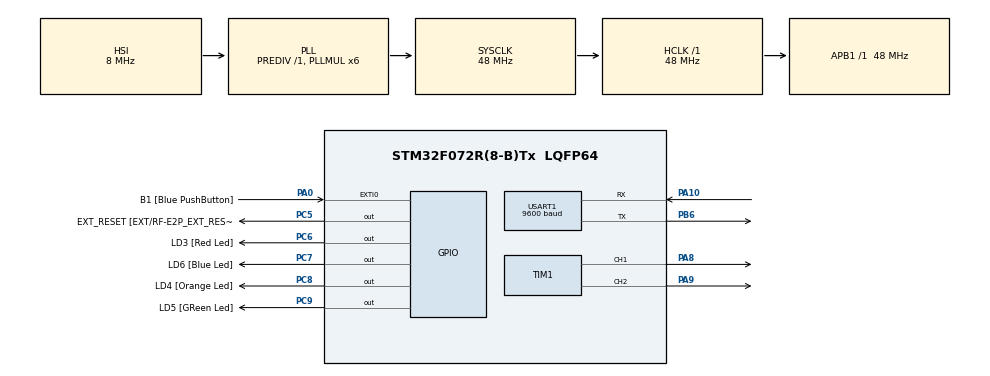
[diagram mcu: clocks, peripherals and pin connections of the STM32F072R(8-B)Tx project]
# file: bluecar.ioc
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Mcu.Family=STM32F0
Mcu.Name=STM32F072R(8-B)Tx
Mcu.Package=LQFP64
NVIC.TIM1_BRK_UP_TRG_COM_IRQn=true\:0\:0\:false\:false\:true
NVIC.TIM1_CC_IRQn=true\:0\:0\:false\:false\:true
NVIC.TIM2_IRQn=true\:0\:0\:false\:false\:true
NVIC.TimeBase=TIM2_IRQn
NVIC.TimeBaseIP=TIM2
NVIC.USART1_IRQn=true\:0\:0\:true\:true\:true\:1
PA0.GPIO_Label=B1 [Blue PushButton]
PA0.GPIO_ModeDefaultEXTI=GPIO_MODE_EVT_RISING
PA0.Signal=GPXTI0
PA10.Mode=Asynchronous
PA10.Signal=USART1_RX
PA13.GPIO_Label=SWDIO
PA13.Signal=SYS_SWDIO
PA14.GPIO_Label=SWCLK
PA14.Signal=SYS_SWCLK
PA8.Signal=S_TIM1_CH1
PA9.Signal=S_TIM1_CH2
PB6.Mode=Asynchronous
PB6.Signal=USART1_TX
PC5.GPIO_Label=EXT_RESET [EXT/RF-E2P_EXT_RESET]
PC5.Signal=GPIO_Output
PC6.GPIO_Label=LD3 [Red Led]
PC6.Signal=GPIO_Output
PC7.GPIO_Label=LD6 [Blue Led]
PC7.Signal=GPIO_Output
PC8.GPIO_Label=LD4 [Orange Led]
PC8.Signal=GPIO_Output
PC9.GPIO_Label=LD5 [GReen Led]
PC9.Signal=GPIO_Output
ProjectManager.HeapSize=0x200
ProjectManager.StackSize=0x400
ProjectManager.TargetToolchain=SW4STM32
RCC.AHBFreq_Value=48000000
RCC.APB1Freq_Value=48000000
RCC.APB1TimFreq_Value=48000000
RCC.HCLKFreq_Value=48000000
RCC.PLLMUL=RCC_PLL_MUL6
RCC.SYSCLKFreq_VALUE=48000000
RCC.SYSCLKSource=RCC_SYSCLKSOURCE_PLLCLK
SH.S_TIM1_CH1.0=TIM1_CH1,PWM Generation1 CH1
SH.S_TIM1_CH2.0=TIM1_CH2,PWM Generation2 CH2
TIM1.Channel-PWM\ Generation1\ CH1=TIM_CHANNEL_1
TIM1.Channel-PWM\ Generation2\ CH2=TIM_CHANNEL_2
USART1.AutoBaudRateEnableParam=UART_ADVFEATURE_AUTOBAUDRATE_DISABLE
USART1.BaudRate=9600
USART1.VirtualMode-Asynchronous=VM_ASYNC
USART1.WordLength=WORDLENGTH_8B
VP_SYS_VS_tim2.Mode=TIM2
board=STM32F072B-DISCO

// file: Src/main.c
/**
  ******************************************************************************
  * File Name          : main.c
  * Description        : Main program body
  ******************************************************************************
  *
  * COPYRIGHT(c) 2017 STMicroelectronics
  *
  * Redistribution and use in source and binary forms, with or without modification,
  * are permitted provided that the following conditions are met:
  *   1. Redistributions of source code must retain the above copyright notice,
  *      this list of conditions and the following disclaimer.
  *   2. Redistributions in binary form must reproduce the above copyright notice,
  *      this list of conditions and the following disclaimer in the documentation
  *      and/or other materials provided with the distribution.
  *   3. Neither the name of STMicroelectronics nor the names of its contributors
  *      may be used to endorse or promote products derived from this software
  *      without specific prior written permission.
  *
  * THIS SOFTWARE IS PROVIDED BY THE COPYRIGHT HOLDERS AND CONTRIBUTORS "AS IS"
  * AND ANY EXPRESS OR IMPLIED WARRANTIES, INCLUDING, BUT NOT LIMITED TO, THE
  * IMPLIED WARRANTIES OF MERCHANTABILITY AND FITNESS FOR A PARTICULAR PURPOSE ARE
  * DISCLAIMED. IN NO EVENT SHALL THE COPYRIGHT HOLDER OR CONTRIBUTORS BE LIABLE
  * FOR ANY DIRECT, INDIRECT, INCIDENTAL, SPECIAL, EXEMPLARY, OR CONSEQUENTIAL
  * DAMAGES (INCLUDING, BUT NOT LIMITED TO, PROCUREMENT OF SUBSTITUTE GOODS OR
  * SERVICES; LOSS OF USE, DATA, OR PROFITS; OR BUSINESS INTERRUPTION) HOWEVER
  * CAUSED AND ON ANY THEORY OF LIABILITY, WHETHER IN CONTRACT, STRICT LIABILITY,
  * OR TORT (INCLUDING NEGLIGENCE OR OTHERWISE) ARISING IN ANY WAY OUT OF THE USE
  * OF THIS SOFTWARE, EVEN IF ADVISED OF THE POSSIBILITY OF SUCH DAMAGE.
  *
  ******************************************************************************
  */
#include "main.h"
#include "stm32f0xx_hal.h"

TIM_HandleTypeDef htim1;

UART_HandleTypeDef huart1;

/* USER CODE BEGIN PV */
/* Private variables ---------------------------------------------------------*/

/* USER CODE END PV */

void SystemClock_Config(void);
void Error_Handler(void);
static void MX_GPIO_Init(void);
static void MX_TIM1_Init(void);
static void MX_USART1_UART_Init(void);
static void MX_NVIC_Init(void);
void HAL_TIM_MspPostInit(TIM_HandleTypeDef *htim);

/* USER CODE BEGIN PFP */
/* Private function prototypes -----------------------------------------------*/

/* USER CODE END PFP */

int main(void)
{

  /* USER CODE BEGIN 1 */

	static uint8_t i = {0xAA, 0x55};

  /* USER CODE END 1 */

  /* MCU Configuration----------------------------------------------------------*/

  /* Reset of all peripherals, Initializes the Flash interface and the Systick. */
  HAL_Init();

  /* Configure the system clock */
  SystemClock_Config();

  /* Initialize all configured peripherals */
  MX_GPIO_Init();
  MX_TIM1_Init();
  MX_USART1_UART_Init();

  /* Initialize interrupts */
  MX_NVIC_Init();

  /* Infinite loop */
  while (1)
  {

	  HAL_UART_Transmit_IT(&huart1, i, 2)

  }

}

/** System Clock Configuration
*/
void SystemClock_Config(void)
{

  RCC_OscInitTypeDef RCC_OscInitStruct;
  RCC_ClkInitTypeDef RCC_ClkInitStruct;
  RCC_PeriphCLKInitTypeDef PeriphClkInit;

    /**Initializes the CPU, AHB and APB busses clocks
    */
  RCC_OscInitStruct.OscillatorType = RCC_OSCILLATORTYPE_HSI;
  RCC_OscInitStruct.HSIState = RCC_HSI_ON;
  RCC_OscInitStruct.HSICalibrationValue = 16;
  RCC_OscInitStruct.PLL.PLLState = RCC_PLL_ON;
  RCC_OscInitStruct.PLL.PLLSource = RCC_PLLSOURCE_HSI;
  RCC_OscInitStruct.PLL.PLLMUL = RCC_PLL_MUL6;
  RCC_OscInitStruct.PLL.PREDIV = RCC_PREDIV_DIV1;
  if (HAL_RCC_OscConfig(&RCC_OscInitStruct) != HAL_OK)
  {
    Error_Handler();
  }

    /**Initializes the CPU, AHB and APB busses clocks
    */
  RCC_ClkInitStruct.ClockType = RCC_CLOCKTYPE_HCLK|RCC_CLOCKTYPE_SYSCLK
                              |RCC_CLOCKTYPE_PCLK1;
  RCC_ClkInitStruct.SYSCLKSource = RCC_SYSCLKSOURCE_PLLCLK;
  RCC_ClkInitStruct.AHBCLKDivider = RCC_SYSCLK_DIV1;
  RCC_ClkInitStruct.APB1CLKDivider = RCC_HCLK_DIV1;

  if (HAL_RCC_ClockConfig(&RCC_ClkInitStruct, FLASH_LATENCY_1) != HAL_OK)
  {
    Error_Handler();
  }

  PeriphClkInit.PeriphClockSelection = RCC_PERIPHCLK_USART1;
  PeriphClkInit.Usart1ClockSelection = RCC_USART1CLKSOURCE_PCLK1;
  if (HAL_RCCEx_PeriphCLKConfig(&PeriphClkInit) != HAL_OK)
  {
    Error_Handler();
  }

    /**Configure the Systick interrupt time
    */
  HAL_SYSTICK_Config(HAL_RCC_GetHCLKFreq()/1000);

    /**Configure the Systick
    */
  HAL_SYSTICK_CLKSourceConfig(SYSTICK_CLKSOURCE_HCLK);

  /* SysTick_IRQn interrupt configuration */
  HAL_NVIC_SetPriority(SysTick_IRQn, 0, 0);
}

/** NVIC Configuration
*/
static void MX_NVIC_Init(void)
{
  /* USART1_IRQn interrupt configuration */
  HAL_NVIC_SetPriority(USART1_IRQn, 0, 0);
  HAL_NVIC_EnableIRQ(USART1_IRQn);
}

/* TIM1 init function */
static void MX_TIM1_Init(void)
{

  TIM_MasterConfigTypeDef sMasterConfig;
  TIM_OC_InitTypeDef sConfigOC;
  TIM_BreakDeadTimeConfigTypeDef sBreakDeadTimeConfig;

  htim1.Instance = TIM1;
  htim1.Init.Prescaler = 0;
  htim1.Init.CounterMode = TIM_COUNTERMODE_UP;
  htim1.Init.Period = 0;
  htim1.Init.ClockDivision = TIM_CLOCKDIVISION_DIV1;
  htim1.Init.RepetitionCounter = 0;
  htim1.Init.AutoReloadPreload = TIM_AUTORELOAD_PRELOAD_DISABLE;
  if (HAL_TIM_PWM_Init(&htim1) != HAL_OK)
  {
    Error_Handler();
  }

  sMasterConfig.MasterOutputTrigger = TIM_TRGO_RESET;
  sMasterConfig.MasterSlaveMode = TIM_MASTERSLAVEMODE_DISABLE;
  if (HAL_TIMEx_MasterConfigSynchronization(&htim1, &sMasterConfig) != HAL_OK)
  {
    Error_Handler();
  }

  sConfigOC.OCMode = TIM_OCMODE_PWM1;
  sConfigOC.Pulse = 0;
  sConfigOC.OCPolarity = TIM_OCPOLARITY_HIGH;
  sConfigOC.OCNPolarity = TIM_OCNPOLARITY_HIGH;
  sConfigOC.OCFastMode = TIM_OCFAST_DISABLE;
  sConfigOC.OCIdleState = TIM_OCIDLESTATE_RESET;
  sConfigOC.OCNIdleState = TIM_OCNIDLESTATE_RESET;
  if (HAL_TIM_PWM_ConfigChannel(&htim1, &sConfigOC, TIM_CHANNEL_1) != HAL_OK)
  {
    Error_Handler();
  }

  if (HAL_TIM_PWM_ConfigChannel(&htim1, &sConfigOC, TIM_CHANNEL_2) != HAL_OK)
  {
    Error_Handler();
  }

  sBreakDeadTimeConfig.OffStateRunMode = TIM_OSSR_DISABLE;
  sBreakDeadTimeConfig.OffStateIDLEMode = TIM_OSSI_DISABLE;
  sBreakDeadTimeConfig.LockLevel = TIM_LOCKLEVEL_OFF;
  sBreakDeadTimeConfig.DeadTime = 0;
  sBreakDeadTimeConfig.BreakState = TIM_BREAK_DISABLE;
  sBreakDeadTimeConfig.BreakPolarity = TIM_BREAKPOLARITY_HIGH;
  sBreakDeadTimeConfig.AutomaticOutput = TIM_AUTOMATICOUTPUT_DISABLE;
  if (HAL_TIMEx_ConfigBreakDeadTime(&htim1, &sBreakDeadTimeConfig) != HAL_OK)
  {
    Error_Handler();
  }

  HAL_TIM_MspPostInit(&htim1);

}

/* USART1 init function */
static void MX_USART1_UART_Init(void)
{

  huart1.Instance = USART1;
  huart1.Init.BaudRate = 9600;
  huart1.Init.WordLength = UART_WORDLENGTH_8B;
  huart1.Init.StopBits = UART_STOPBITS_1;
  huart1.Init.Parity = UART_PARITY_NONE;
  huart1.Init.Mode = UART_MODE_TX_RX;
  huart1.Init.HwFlowCtl = UART_HWCONTROL_NONE;
  huart1.Init.OverSampling = UART_OVERSAMPLING_16;
  huart1.Init.OneBitSampling = UART_ONE_BIT_SAMPLE_DISABLE;
  huart1.AdvancedInit.AdvFeatureInit = UART_ADVFEATURE_NO_INIT;
  if (HAL_UART_Init(&huart1) != HAL_OK)
  {
    Error_Handler();
  }

}

/** Configure pins as
        * Analog
        * Input
        * Output
        * EVENT_OUT
        * EXTI
*/
static void MX_GPIO_Init(void)
{

  GPIO_InitTypeDef GPIO_InitStruct;

  /* GPIO Ports Clock Enable */
  __HAL_RCC_GPIOA_CLK_ENABLE();
  __HAL_RCC_GPIOC_CLK_ENABLE();
  __HAL_RCC_GPIOB_CLK_ENABLE();

  /*Configure GPIO pin Output Level */
  HAL_GPIO_WritePin(GPIOC, EXT_RESET_Pin|LD3_Pin|LD6_Pin|LD4_Pin
                          |LD5_Pin, GPIO_PIN_RESET);

  /*Configure GPIO pin : B1_Pin */
  GPIO_InitStruct.Pin = B1_Pin;
  GPIO_InitStruct.Mode = GPIO_MODE_EVT_RISING;
  GPIO_InitStruct.Pull = GPIO_NOPULL;
  HAL_GPIO_Init(B1_GPIO_Port, &GPIO_InitStruct);

  /*Configure GPIO pins : EXT_RESET_Pin LD3_Pin LD6_Pin LD4_Pin
                           LD5_Pin */
  GPIO_InitStruct.Pin = EXT_RESET_Pin|LD3_Pin|LD6_Pin|LD4_Pin
                          |LD5_Pin;
  GPIO_InitStruct.Mode = GPIO_MODE_OUTPUT_PP;
  GPIO_InitStruct.Pull = GPIO_NOPULL;
  GPIO_InitStruct.Speed = GPIO_SPEED_FREQ_LOW;
  HAL_GPIO_Init(GPIOC, &GPIO_InitStruct);

}

void HAL_TIM_PeriodElapsedCallback(TIM_HandleTypeDef *htim)
{
  if (htim->Instance == TIM2) {
    HAL_IncTick();
  }
}

void Error_Handler(void)
{
  while(1)
  {
  }
}

/************************ (C) COPYRIGHT STMicroelectronics *****END OF FILE****/
